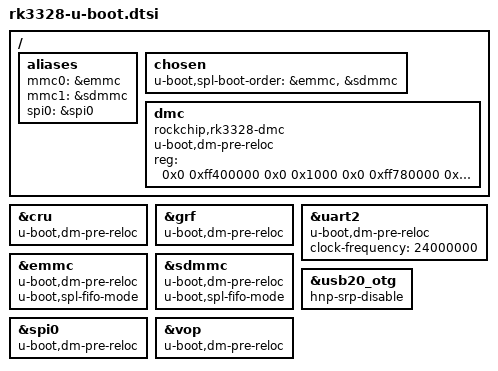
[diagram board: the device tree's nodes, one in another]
// SPDX-License-Identifier: GPL-2.0+
/*
 * (C) Copyright 2019 Rockchip Electronics Co., Ltd
 */

#include "rockchip-u-boot.dtsi"

/ {
	aliases {
		mmc0 = &emmc;
		mmc1 = &sdmmc;
		spi0 = &spi0;
	};

	chosen {
		u-boot,spl-boot-order = &emmc, &sdmmc;
	};

	dmc: dmc {
		u-boot,dm-pre-reloc;
		compatible = "rockchip,rk3328-dmc";
		reg = <0x0 0xff400000 0x0 0x1000
		       0x0 0xff780000 0x0 0x3000
		       0x0 0xff100000 0x0 0x1000
		       0x0 0xff440000 0x0 0x1000
		       0x0 0xff720000 0x0 0x1000
		       0x0 0xff798000 0x0 0x1000>;
	};
};

&cru {
	u-boot,dm-pre-reloc;
};

&grf {
	u-boot,dm-pre-reloc;
};

&uart2 {
	u-boot,dm-pre-reloc;
	clock-frequency = <24000000>;
};

&emmc {
	u-boot,dm-pre-reloc;

	/* mmc to sram can't do dma, prevent aborts transfering TF-A parts */
	u-boot,spl-fifo-mode;
};

&sdmmc {
	u-boot,dm-pre-reloc;

	/* mmc to sram can't do dma, prevent aborts transfering TF-A parts */
	u-boot,spl-fifo-mode;
};

&usb20_otg {
	hnp-srp-disable;
};

&spi0 {
	u-boot,dm-pre-reloc;
};

&vop {
	u-boot,dm-pre-reloc;
};
